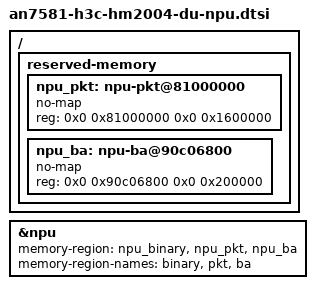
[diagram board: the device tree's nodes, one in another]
// SPDX-License-Identifier: (GPL-2.0-only OR BSD-2-Clause)
/*
 * H3C HM2004-DU —— WiFi→PON 硬件转发（NPU RX 卸载）叠加层
 *
 * ============================================================
 * 保守版（step 1）：只加内存预留，不改 NPU 现有启动行为
 * ============================================================
 *
 * 背景（实机实测，2026-11-19）：
 *   当前固件的 NPU 用上游标准流程就能正常启动：
 *       airoha-npu 1e900000.npu: NPU fw version: 1456.62
 *       /sys/kernel/debug/ppe/config -> npu_attached: 1
 *   它加载的是驱动内置名 en7581_npu_rv32.bin（120KB 通用版），
 *   DTS 只预留 binary 区，没有 firmware-name、没有 legacy 标记。
 *
 * 因此本版【刻意不做】三件事：
 *   1. 不设 firmware-name —— 避免把能工作的通用固件换成 MT7916 专用
 *      固件（上一轮换成 MT7916 固件 + 标准启动流程 = 946 次超时）
 *   2. 不设 airoha,legacy-wlan-mailbox —— 避免触发 legacy boot 分支，
 *      该分支会跳过 MIB/BOOT_BASE 配置，属未验证的逆向推测
 *   3. 不设 airoha,mt7916-rx-only-memory —— 同理，避免影响启动判定
 *
 * 只保留 mt76 侧 npu.c 真正需要的两个额外内存区：pkt 与 ba。
 * 上游 airoha_npu_wlan_init_memory() 按名字查找它们：
 *   tx-bufid / pkt / tx-pkt / ba
 * 其中 tx-* 由内核补丁 400 改为「DTS 有才下发」，所以这里只给 pkt/ba，
 * 正是 RX-only 设计需要的组合。
 *
 * 内存布局依据原厂 QWRT 固件 DTB（见 reverse-out/board.dts）：
 *   npu-pkt @0x81000000  22MB   —— 与原厂同址
 *   npu-ba  @0x90c06800   2MB   —— 与原厂同址
 * 上游 en7581.dtsi 已占用 0x80000000(atf) / 0x84000000(npu-binary)
 * / 0x87000000(qdma0) / 0x89000000(qdma1)，0x81000000 空闲可安全占用。
 */

/ {
	reserved-memory {
		#address-cells = <2>;
		#size-cells = <2>;
		ranges;

		npu_pkt: npu-pkt@81000000 {
			no-map;
			reg = <0x0 0x81000000 0x0 0x1600000>;
		};

		npu_ba: npu-ba@90c06800 {
			no-map;
			reg = <0x0 0x90c06800 0x0 0x200000>;
		};
	};
};

/*
 * NPU 节点：只追加两个内存区，其余保持上游默认。
 *
 * memory-region 顺序必须与 memory-region-names 对应；
 * 上游驱动用 of_reserved_mem_region_to_resource_byname() 按名字取，
 * 所以顺序不敏感，但保持 binary 在首位与原厂一致。
 */
&npu {
	status = "okay";

	memory-region = <&npu_binary>, <&npu_pkt>, <&npu_ba>;
	memory-region-names = "binary", "pkt", "ba";
};
